AUTOSAR XML (schema 314)
package /ComponentType
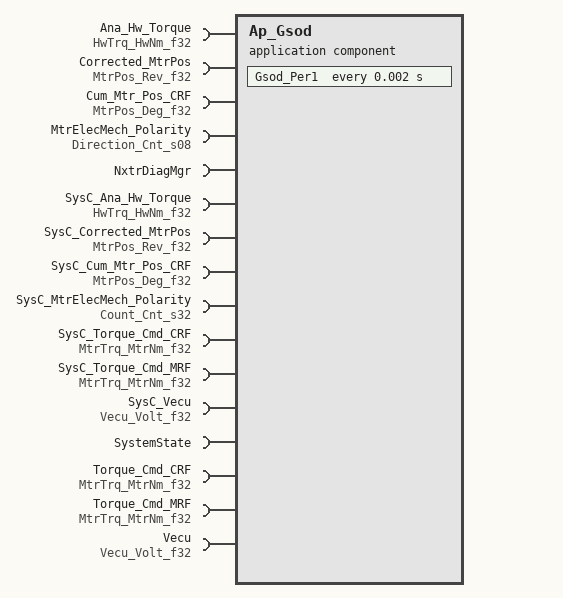
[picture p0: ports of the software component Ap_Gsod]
  application software component type Ap_Gsod
    16 x require port:
      Ana_Hw_Torque: unqueued-receiver-com-spec{data-element=HwNm_f32, init-value=D_ZERO_ULS_F32}, required-interface=HwTrq_HwNm_f32
      Corrected_MtrPos: unqueued-receiver-com-spec{data-element=Rev_f32, init-value=D_ZERO_ULS_F32}, required-interface=MtrPos_Rev_f32
      Cum_Mtr_Pos_CRF: unqueued-receiver-com-spec{data-element=Deg_f32, init-value=D_ZERO_ULS_F32}, required-interface=MtrPos_Deg_f32
      MtrElecMech_Polarity: unqueued-receiver-com-spec{data-element=Cnt_s08, init-value=D_ZERO_CNT_S8}, required-interface=Direction_Cnt_s08
      NxtrDiagMgr: required-com-specs=[GetNTCActive, GetNTCFailed, GetNTCStatus, SetNTCStatus], required-interface=NxtrDiagMgr
      SysC_Ana_Hw_Torque: unqueued-receiver-com-spec{data-element=HwNm_f32, init-value=D_ZERO_ULS_F32}, required-interface=HwTrq_HwNm_f32
      SysC_Corrected_MtrPos: unqueued-receiver-com-spec{data-element=Rev_f32, init-value=D_ZERO_ULS_F32}, required-interface=MtrPos_Rev_f32
      SysC_Cum_Mtr_Pos_CRF: unqueued-receiver-com-spec{data-element=Deg_f32, init-value=D_ZERO_ULS_F32}, required-interface=MtrPos_Deg_f32
      SysC_MtrElecMech_Polarity: unqueued-receiver-com-spec{data-element=Cnt_s32, init-value=D_ZERO_CNT_S32}, required-interface=Count_Cnt_s32
      SysC_Torque_Cmd_CRF: unqueued-receiver-com-spec{data-element=MtrNm_f32, init-value=D_ZERO_ULS_F32}, required-interface=MtrTrq_MtrNm_f32
      SysC_Torque_Cmd_MRF: unqueued-receiver-com-spec{data-element=MtrNm_f32, init-value=D_ZERO_ULS_F32}, required-interface=MtrTrq_MtrNm_f32
      SysC_Vecu: unqueued-receiver-com-spec{data-element=Volt_f32, init-value=D_VECUMIN_VOLTS_F32}, required-interface=Vecu_Volt_f32
      SystemState: required-interface=SystemState
      Torque_Cmd_CRF: unqueued-receiver-com-spec{data-element=MtrNm_f32, init-value=D_ZERO_ULS_F32}, required-interface=MtrTrq_MtrNm_f32
      Torque_Cmd_MRF: unqueued-receiver-com-spec{data-element=MtrNm_f32, init-value=D_ZERO_ULS_F32}, required-interface=MtrTrq_MtrNm_f32
      Vecu: unqueued-receiver-com-spec{data-element=Volt_f32, init-value=D_VECUMIN_VOLTS_F32}, required-interface=Vecu_Volt_f32
  internal behavior Ap_Gsod_InternalBehavior: component=Ap_Gsod
    timing event TMT_Gsod_Per1: mode-dependency=dependent-on-mode=SystemState.Mode.OFF, start-on-event=Gsod_Per1, period=0.002
    port-api-options:
      enable-take-address=false, indirect-api=false, port=Ana_Hw_Torque
      enable-take-address=false, indirect-api=false, port=Corrected_MtrPos
      enable-take-address=false, indirect-api=false, port=Cum_Mtr_Pos_CRF
      enable-take-address=false, indirect-api=false, port=MtrElecMech_Polarity
      enable-take-address=false, indirect-api=false, port=NxtrDiagMgr
      enable-take-address=false, indirect-api=false, port=SysC_Ana_Hw_Torque
      enable-take-address=false, indirect-api=false, port=SysC_Corrected_MtrPos
      enable-take-address=false, indirect-api=false, port=SysC_Cum_Mtr_Pos_CRF
      enable-take-address=false, indirect-api=false, port=SysC_MtrElecMech_Polarity
      enable-take-address=false, indirect-api=false, port=SysC_Torque_Cmd_CRF
      enable-take-address=false, indirect-api=false, port=SysC_Torque_Cmd_MRF
      enable-take-address=false, indirect-api=false, port=SysC_Vecu
      enable-take-address=false, indirect-api=false, port=SystemState
      enable-take-address=false, indirect-api=false, port=Torque_Cmd_CRF
      enable-take-address=false, indirect-api=false, port=Torque_Cmd_MRF
      enable-take-address=false, indirect-api=false, port=Vecu
    runnable Gsod_Per1
      14 x data receive point:
        REC_Ana_Hw_Torque_HwNm_f32: data-element=Ana_Hw_Torque.HwNm_f32
        REC_Corrected_MtrPos_Rev_f32: data-element=Corrected_MtrPos.Rev_f32
        REC_Cum_Mtr_Pos_CRF_Deg_f32: data-element=Cum_Mtr_Pos_CRF.Deg_f32
        REC_MtrElecMech_Polarity_Cnt_s08: data-element=MtrElecMech_Polarity.Cnt_s08
        REC_SysC_Ana_Hw_Torque_HwNm_f32: data-element=SysC_Ana_Hw_Torque.HwNm_f32
        REC_SysC_Corrected_MtrPos_Rev_f32: data-element=SysC_Corrected_MtrPos.Rev_f32
        REC_SysC_Cum_Mtr_Pos_CRF_Deg_f32: data-element=SysC_Cum_Mtr_Pos_CRF.Deg_f32
        REC_SysC_MtrElecMech_Polarity_Cnt_s32: data-element=SysC_MtrElecMech_Polarity.Cnt_s32
        REC_SysC_Torque_Cmd_CRF_MtrNm_f32: data-element=SysC_Torque_Cmd_CRF.MtrNm_f32
        REC_SysC_Torque_Cmd_MRF_MtrNm_f32: data-element=SysC_Torque_Cmd_MRF.MtrNm_f32
        REC_SysC_Vecu_Volt_f32: data-element=SysC_Vecu.Volt_f32
        REC_Torque_Cmd_CRF_MtrNm_f32: data-element=Torque_Cmd_CRF.MtrNm_f32
        REC_Torque_Cmd_MRF_MtrNm_f32: data-element=Torque_Cmd_MRF.MtrNm_f32
        REC_Vecu_Volt_f32: data-element=Vecu.Volt_f32
      sync call SC_NxtrDiagMgr_SetNTCStatus: operation=NxtrDiagMgr.SetNTCStatus, timeout=0
  swc implementation Ap_Gsod_Implementation: behavior=Ap_Gsod_InternalBehavior
    code-descriptors:
      code Code: type=SRC
